# APM32F403 register map
File version: 1.0
CPU: CM4 r1p0, little endian, no MPU, no FPU, 4 interrupt priority bits
Registers are 32-bit, read-write, reset 0x0 unless marked. A register's access mark holds for its fields unless they carry their own. Offsets are from the block's base; [hi:lo] are bit positions; {n}, {i} and the like mark numbered series; 'fields as' and 'values as' point back to an identical list.

## SPI1 — Serial peripheral interface
Base 0x40013000
Same registers: SPI2 0x40003800
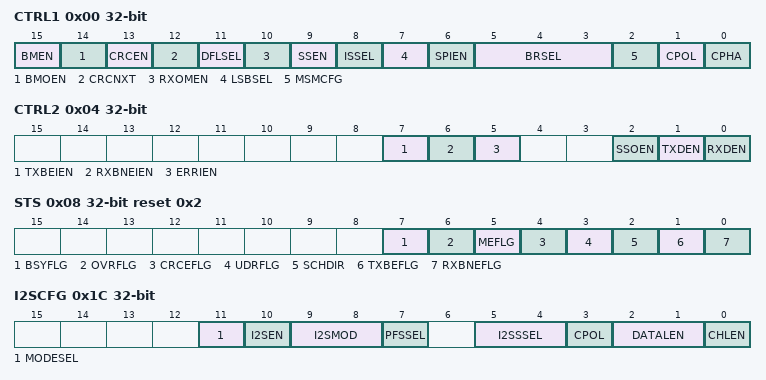
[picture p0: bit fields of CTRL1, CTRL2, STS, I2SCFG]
0x00 CTRL1 — control register 1
  [15] BMEN — Bidirectional data mode enable
  [14] BMOEN — Output enable in bidirectional mode
  [13] CRCEN — Hardware CRC calculation enable
  [12] CRCNXT — CRC transfer next
  [11] DFLSEL — Data frame format
  [10] RXOMEN — Receive only
  [9] SSEN — Software slave management
  [8] ISSEL — Internal slave select
  [7] LSBSEL — Frame format
  [6] SPIEN — SPI enable
  [5:3] BRSEL — Baud rate control
  [2] MSMCFG — Master selection
  [1] CPOL — Clock polarity
  [0] CPHA — Clock phase
0x04 CTRL2 — control register 2
  [7] TXBEIEN — Tx buffer empty interrupt enable
  [6] RXBNEIEN — RX buffer not empty interrupt enable
  [5] ERRIEN — Error interrupt enable
  [2] SSOEN — SS output enable
  [1] TXDEN — Tx buffer DMA enable
  [0] RXDEN — Rx buffer DMA enable
0x08 STS access per field reset 0x2 — status register
  [7] BSYFLG ro — Busy flag
  [6] OVRFLG ro — Overrun flag
  [5] MEFLG ro — Mode fault
  [4] CRCEFLG rw — CRC error flag
  [3] UDRFLG ro — Underrun flag
  [2] SCHDIR ro — Channel side
  [1] TXBEFLG ro — Transmit buffer empty
  [0] RXBNEFLG ro — Receive buffer not empty
0x0C DATA
  [15:0] DATA
0x10 CRCPOLY reset 0x7 — CRC polynomial register
  [15:0] CRCPOLY
0x14 RXCRC ro
  [15:0] RXCRC
0x18 TXCRC ro
  [15:0] TXCRC
0x1C I2SCFG — I2S configuration register
  [11] MODESEL — I2S mode selection
  [10] I2SEN — I2S Enable
  [9:8] I2SMOD — I2S configuration mode
  [7] PFSSEL — PCM frame synchronization
  [5:4] I2SSSEL — I2S standard selection
  [3] CPOL — Steady state clock polarity
  [2:1] DATALEN — Data length to be transferred
  [0] CHLEN — Channel length (number of bits per audio channel)
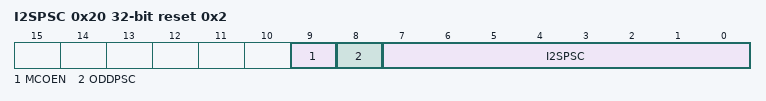
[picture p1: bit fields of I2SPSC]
0x20 I2SPSC reset 0x2 — I2S prescaler register
  [9] MCOEN — Master clock output enable
  [8] ODDPSC — Odd factor for the prescaler
  [7:0] I2SPSC — I2S Linear prescaler

## DMA2 — DMA controller
Base 0x40020400
Same registers: DMA1 0x40020000
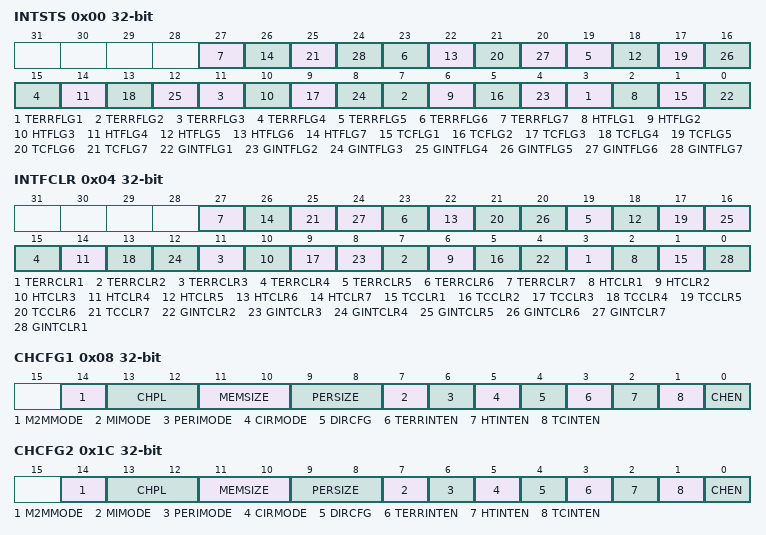
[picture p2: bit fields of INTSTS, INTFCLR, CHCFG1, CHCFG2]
0x00 INTSTS ro — DMA Interrupt status register (DMA_INTSTS)
  [4n-1] TERRFLG{n} (n=1..7) — Channel {n} Transfer Error flag
  [4n-2] HTFLG{n} (n=1..7) — Channel {n} Half Transfer Complete flag
  [4n-3] TCFLG{n} (n=1..7) — Channel {n} Transfer Complete flag
  [4n-4] GINTFLG{n} (n=1..7) — Channel {n} Global interrupt flag
0x04 INTFCLR wo — DMA Interrupt reset register (DMA_INTFCLR)
  [4n-1] TERRCLR{n} (n=1..7) — Channel {n} Transfer Error reset
  [4n-2] HTCLR{n} (n=1..7) — Channel {n} Half Transfer reset
  [4n-3] TCCLR{n} (n=1..7) — Channel {n} Transfer Complete reset
  [4n-4] GINTCLR{n} (n=2..7) — Channel {n} Global interrupt reset
  [0] GINTCLR1 — Channel 1 Global interrupt resetr
0x08 CHCFG1 — DMA channel 1 configuration register
  [14] M2MMODE — Memory to memory mode
  [13:12] CHPL — Channel Priority level
  [11:10] MEMSIZE — Memory size
  [9:8] PERSIZE — Peripheral size
  [7] MIMODE — Memory increment mode
  [6] PERIMODE — Peripheral increment mode
  [5] CIRMODE — Circular mode
  [4] DIRCFG — Data transfer direction
  [3] TERRINTEN — Transfer error interrupt enable
  [2] HTINTEN — Half Transfer interrupt enable
  [1] TCINTEN — Transfer complete interrupt enable
  [0] CHEN — Channel enable
0x0C CHNDATA1 — DMA channel 1 number of data register
  [15:0] NDATAT — Number of data to transfer
0x10 CHPADDR1 — DMA channel 1 peripheral address register
  [31:0] PERADDR — Peripheral address
{0x0+0x14*i} CHMADDR{i} (i=1..7) — DMA channel {i} memory address register
  [31:0] MEMADDR — Memory address
0x1C CHCFG2 — DMA channel 2 configuration register
  fields as CHCFG1
0x20 CHNDATA2 — DMA channel 2 number of data register
  [15:0] NDATAT — Number of data to transfer
0x24 CHPADDR2 — DMA channel 2 peripheral address register
  [31:0] PERADDR — Peripheral address
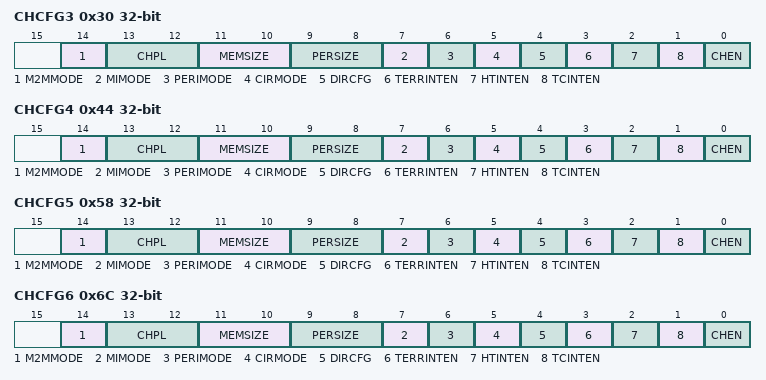
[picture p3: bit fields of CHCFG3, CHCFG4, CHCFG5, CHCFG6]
0x30 CHCFG3 — DMA channel 3 configuration register
  fields as CHCFG1
0x34 CHNDATA3 — DMA channel 3 number of data register
  [15:0] NDATAT — Number of data to transfer
0x38 CHPADDR3 — DMA channel 3 peripheral address register
  [31:0] PERADDR — Peripheral address
0x44 CHCFG4 — DMA channel 4 configuration register
  fields as CHCFG1
0x48 CHNDATA4 — DMA channel 4 number of data register
  [15:0] NDATAT — Number of data to transfer
0x4C CHPADDR4 — DMA channel 4 peripheral address register
  [31:0] PERADDR — Peripheral address
0x58 CHCFG5 — DMA channel 5 configuration register
  fields as CHCFG1
0x5C CHNDATA5 — DMA channel 5 number of data register
  [15:0] NDATAT — Number of data to transfer
0x60 CHPADDR5 — DMA channel 5 peripheral address register
  [31:0] PERADDR — Peripheral address
0x6C CHCFG6 — DMA channel 6 configuration register
  fields as CHCFG1
0x70 CHNDATA6 — DMA channel 6 number of data register
  [15:0] NDATAT — Number of data to transfer
0x74 CHPADDR6 — DMA channel 6 peripheral address register
  [31:0] PERADDR — Peripheral address
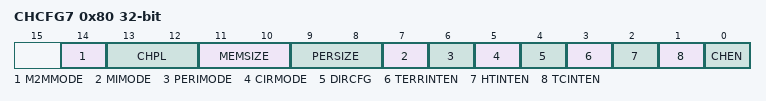
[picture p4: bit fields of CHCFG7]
0x80 CHCFG7 — DMA channel 7 configuration register
  fields as CHCFG1
0x84 CHNDATA7 — DMA channel 7 number of data register
  [15:0] NDATAT — Number of data to transfer
0x88 CHPADDR7 — DMA channel 7 peripheral address register
  [31:0] PERADDR — Peripheral address
